VERSION ""

NS_ :

BS_:

BU_:

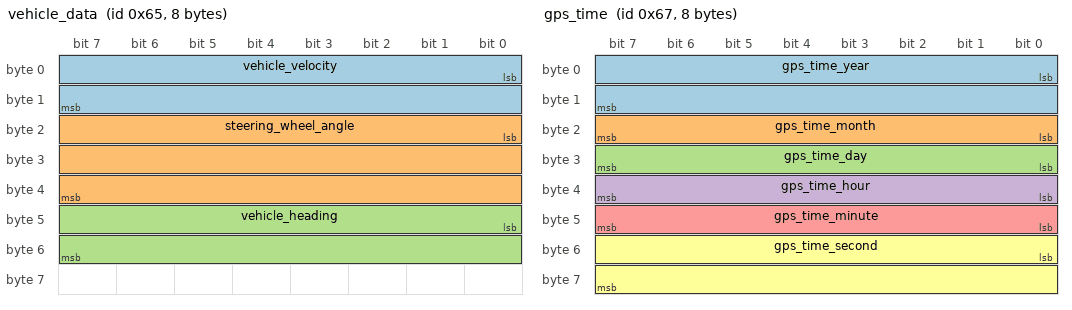
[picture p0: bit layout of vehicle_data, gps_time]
BO_ 101 vehicle_data: 8 Vector__XXX
 SG_ vehicle_velocity : 0|16@1- (0.01,0) [-200|200] "" Vector__XXX
 SG_ steering_wheel_angle : 16|24@1- (0.01,0) [-720|720] "" Vector__XXX
 SG_ vehicle_heading : 40|16@1- (0.01,0) [-180|180] "" Vector__XXX

BO_ 102 longtitude_latitude: 8 Vector__XXX
 SG_ longitude : 0|32@1- (1e-07,0) [-180|180] "" Vector__XXX
 SG_ latitude : 32|32@1- (1e-07,0) [-90|90] "" Vector__XXX

BO_ 103 gps_time: 8 Vector__XXX
 SG_ gps_time_year : 0|16@1+ (1,0) [2000|2200] "" Vector__XXX
 SG_ gps_time_month : 16|8@1+ (1,0) [1|12] "" Vector__XXX
 SG_ gps_time_day : 24|8@1+ (1,0) [1|31] "" Vector__XXX
 SG_ gps_time_hour : 32|8@1+ (1,0) [0|23] "" Vector__XXX
 SG_ gps_time_minute : 40|8@1+ (1,0) [0|59] "" Vector__XXX
 SG_ gps_time_second : 48|16@1+ (0.001,0) [0|60] "" Vector__XXX

BO_ 104 float1: 8 Vector__XXX
 SG_ user_data1 : 0|32@1- (1,0) [-3.4e+38|3.4e+38] "" Vector__XXX
 SG_ user_data2 : 32|32@1- (1,0) [-3.4e+38|3.4e+38] "" Vector__XXX

BO_ 105 float2: 8 Vector__XXX
 SG_ user_data3 : 0|32@1- (1,0) [-3.4e+38|3.4e+38] "" Vector__XXX
 SG_ user_data4 : 32|32@1- (1,0) [-3.4e+38|3.4e+38] "" Vector__XXX

BO_ 106 float3: 8 Vector__XXX
 SG_ user_data5 : 0|32@1- (1,0) [-3.4e+38|3.4e+38] "" Vector__XXX
 SG_ user_data6 : 32|32@1- (1,0) [-3.4e+38|3.4e+38] "" Vector__XXX

BO_ 107 float4: 8 Vector__XXX
 SG_ user_data7 : 0|32@1- (1,0) [-3.4e+38|3.4e+38] "" Vector__XXX
 SG_ user_data8 : 32|32@1- (1,0) [-3.4e+38|3.4e+38] "" Vector__XXX

BO_ 108 float5: 8 Vector__XXX
 SG_ user_data9 : 0|32@1- (1,0) [-3.4e+38|3.4e+38] "" Vector__XXX
 SG_ user_data10 : 32|32@1- (1,0) [-3.4e+38|3.4e+38] "" Vector__XXX

BO_ 109 double1: 8 Vector__XXX
 SG_ user_data11 : 0|64@1- (1,0) [-1.8e+307|1.8e+307] "" Vector__XXX

BO_ 110 double2: 8 Vector__XXX
 SG_ user_data12 : 0|64@1- (1,0) [-1.8e+307|1.8e+307] "" Vector__XXX

BO_ 111 double3: 8 Vector__XXX
 SG_ user_data13 : 0|64@1- (1,0) [-1.8e+307|1.8e+307] "" Vector__XXX

BO_ 112 double4: 8 Vector__XXX
 SG_ user_data14 : 0|64@1- (1,0) [-1.8e+307|1.8e+307] "" Vector__XXX

BO_ 113 double5: 8 Vector__XXX
 SG_ user_data15 : 0|64@1- (1,0) [-1.8e+307|1.8e+307] "" Vector__XXX

BO_ 114 double6: 8 Vector__XXX
 SG_ user_data16 : 0|64@1- (1,0) [-1.8e+307|1.8e+307] "" Vector__XXX

BO_ 115 double7: 8 Vector__XXX
 SG_ user_data17 : 0|64@1- (1,0) [-1.8e+307|1.8e+307] "" Vector__XXX

BO_ 116 double8: 8 Vector__XXX
 SG_ user_data18 : 0|64@1- (1,0) [-1.8e+307|1.8e+307] "" Vector__XXX

BO_ 117 double9: 8 Vector__XXX
 SG_ user_data19 : 0|64@1- (1,0) [-1.8e+307|1.8e+307] "" Vector__XXX

BO_ 118 double10: 8 Vector__XXX
 SG_ user_data20 : 0|64@1- (1,0) [-1.8e+307|1.8e+307] "" Vector__XXX

SIG_VALTYPE_ 104 user_data1 : 1;
SIG_VALTYPE_ 104 user_data2 : 1;
SIG_VALTYPE_ 105 user_data3 : 1;
SIG_VALTYPE_ 105 user_data4 : 1;
SIG_VALTYPE_ 106 user_data5 : 1;
SIG_VALTYPE_ 106 user_data6 : 1;
SIG_VALTYPE_ 107 user_data7 : 1;
SIG_VALTYPE_ 107 user_data8 : 1;
SIG_VALTYPE_ 108 user_data9 : 1;
SIG_VALTYPE_ 108 user_data10 : 1;
SIG_VALTYPE_ 109 user_data11 : 2;
SIG_VALTYPE_ 110 user_data12 : 2;
SIG_VALTYPE_ 111 user_data13 : 2;
SIG_VALTYPE_ 112 user_data14 : 2;
SIG_VALTYPE_ 113 user_data15 : 2;
SIG_VALTYPE_ 114 user_data16 : 2;
SIG_VALTYPE_ 115 user_data17 : 2;
SIG_VALTYPE_ 116 user_data18 : 2;
SIG_VALTYPE_ 117 user_data19 : 2;
SIG_VALTYPE_ 118 user_data20 : 2;
